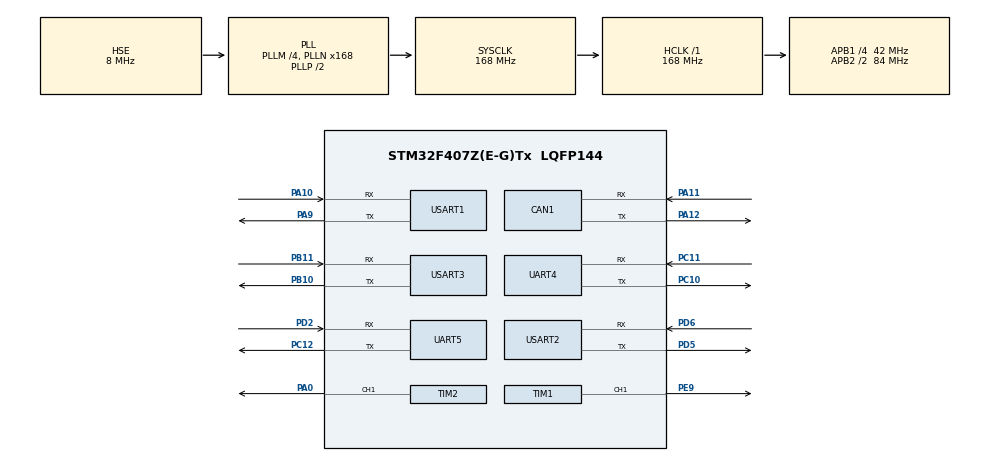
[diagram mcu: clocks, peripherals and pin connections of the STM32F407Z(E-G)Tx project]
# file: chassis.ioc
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CAN1.CalculateTimeBit=1142
CAN1.CalculateTimeQuantum=380.95238095238096
Mcu.Family=STM32F4
Mcu.Name=STM32F407Z(E-G)Tx
Mcu.Package=LQFP144
NVIC.CAN1_RX0_IRQn=true\:0\:0\:false\:false\:true\:true
NVIC.PriorityGroup=NVIC_PRIORITYGROUP_4
NVIC.UART5_IRQn=true\:0\:0\:false\:false\:true\:true
PA0-WKUP.Signal=S_TIM2_CH1_ETR
PA10.Mode=Asynchronous
PA10.Signal=USART1_RX
PA11.Mode=Master
PA11.Signal=CAN1_RX
PA12.Mode=Master
PA12.Signal=CAN1_TX
PA13.Mode=Serial_Wire
PA13.Signal=SYS_JTMS-SWDIO
PA14.Mode=Serial_Wire
PA14.Signal=SYS_JTCK-SWCLK
PA9.Mode=Asynchronous
PA9.Signal=USART1_TX
PB10.Mode=Asynchronous
PB10.Signal=USART3_TX
PB11.Mode=Asynchronous
PB11.Signal=USART3_RX
PC10.Mode=Asynchronous
PC10.Signal=UART4_TX
PC11.Mode=Asynchronous
PC11.Signal=UART4_RX
PC12.Mode=Asynchronous
PC12.Signal=UART5_TX
PD2.Mode=Asynchronous
PD2.Signal=UART5_RX
PD5.Mode=Asynchronous
PD5.Signal=USART2_TX
PD6.Mode=Asynchronous
PD6.Signal=USART2_RX
PE9.Signal=S_TIM1_CH1
PH0-OSC_IN.Mode=HSE-External-Oscillator
PH0-OSC_IN.Signal=RCC_OSC_IN
PH1-OSC_OUT.Mode=HSE-External-Oscillator
PH1-OSC_OUT.Signal=RCC_OSC_OUT
ProjectManager.HeapSize=0x800
ProjectManager.StackSize=0x400
ProjectManager.TargetToolchain=EWARM
RCC.48MHZClocksFreq_Value=84000000
RCC.AHBFreq_Value=168000000
RCC.APB1CLKDivider=RCC_HCLK_DIV4
RCC.APB1Freq_Value=42000000
RCC.APB1TimFreq_Value=84000000
RCC.APB2CLKDivider=RCC_HCLK_DIV2
RCC.APB2Freq_Value=84000000
RCC.APB2TimFreq_Value=168000000
RCC.CortexFreq_Value=168000000
RCC.HCLKFreq_Value=168000000
RCC.HSE_VALUE=8000000
RCC.HSI_VALUE=16000000
RCC.LSE_VALUE=32768
RCC.PLLM=4
RCC.PLLN=168
RCC.PLLSourceVirtual=RCC_PLLSOURCE_HSE
RCC.SYSCLKFreq_VALUE=168000000
RCC.SYSCLKSource=RCC_SYSCLKSOURCE_PLLCLK
RCC.VCOOutputFreq_Value=336000000
SH.S_TIM1_CH1.0=TIM1_CH1,PWM Generation1 CH1
SH.S_TIM2_CH1_ETR.0=TIM2_CH1,PWM Generation1 CH1
TIM1.Channel-PWM\ Generation1\ CH1=TIM_CHANNEL_1
TIM2.Channel-PWM\ Generation1\ CH1=TIM_CHANNEL_1
UART4.VirtualMode=Asynchronous
UART5.VirtualMode=Asynchronous
USART1.VirtualMode=VM_ASYNC
USART2.VirtualMode=VM_ASYNC
USART3.VirtualMode=VM_ASYNC
board=chassis

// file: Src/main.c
/*******************************************************************************
Copyright:      2018/12/18
File name:      main.c
Description:    程序入口，包含系统时钟配置，外设初始化。
Author:         徐铭远，王云轩
Version：       底盘贝塞尔曲线+action全场定位
Data:           2018/12/18 22:36
History:        删去vega.c文件
*******************************************************************************/
#include "main.h"
#include "stm32f4xx_hal.h"
#include "can.h"
#include "tim.h"
#include "usart.h"
#include "gpio.h"
#include "maxon.h"
#include "cmd.h"
#include "cmd_func.h"
#include "chassis.h"
#include "vega.h"
#include "dma.h"

int main_flag = 0;
int chassis_flag = 0;

void SystemClock_Config(void);

void main()
{
    HAL_Init();
    SystemClock_Config();

    MX_GPIO_Init();
    MX_DMA_Init();
    MX_CAN1_Init();
    MX_TIM1_Init();
    MX_UART5_Init();
    MX_USART2_UART_Init();
    MX_USART1_UART_Init();
    MX_USART3_UART_Init();
    MX_UART4_Init();
    MX_TIM2_Init();

    cmd_init();
    can_init();
    chassis_init();

    uprintf(CMD_USART,"start...\r\n");
    main_flag = 1;
    usart_init();//在里面开串口接收中断
    while (1)
    {
        //uprintf(CMD_USART,"start...\r\n");
        usart_exc();
        if(chassis_flag == 1)
        {
            chassis_exe();
            chassis_flag = 0;
        }
    }

}

/** System Clock Configuration
*/
void SystemClock_Config(void)
{

    RCC_OscInitTypeDef RCC_OscInitStruct;
    RCC_ClkInitTypeDef RCC_ClkInitStruct;

    /**Configure the main internal regulator output voltage
    */
    __HAL_RCC_PWR_CLK_ENABLE();

    __HAL_PWR_VOLTAGESCALING_CONFIG(PWR_REGULATOR_VOLTAGE_SCALE1);

    /**Initializes the CPU, AHB and APB busses clocks
    */
    RCC_OscInitStruct.OscillatorType = RCC_OSCILLATORTYPE_HSE;
    RCC_OscInitStruct.HSEState = RCC_HSE_ON;
    RCC_OscInitStruct.PLL.PLLState = RCC_PLL_ON;
    RCC_OscInitStruct.PLL.PLLSource = RCC_PLLSOURCE_HSE;
    RCC_OscInitStruct.PLL.PLLM = 4;
    RCC_OscInitStruct.PLL.PLLN = 168;
    RCC_OscInitStruct.PLL.PLLP = RCC_PLLP_DIV2;
    RCC_OscInitStruct.PLL.PLLQ = 4;
    if (HAL_RCC_OscConfig(&RCC_OscInitStruct) != HAL_OK)
    {
        _Error_Handler(__FILE__, __LINE__);
    }

    /**Initializes the CPU, AHB and APB busses clocks
    */
    RCC_ClkInitStruct.ClockType = RCC_CLOCKTYPE_HCLK|RCC_CLOCKTYPE_SYSCLK
        |RCC_CLOCKTYPE_PCLK1|RCC_CLOCKTYPE_PCLK2;
    RCC_ClkInitStruct.SYSCLKSource = RCC_SYSCLKSOURCE_PLLCLK;
    RCC_ClkInitStruct.AHBCLKDivider = RCC_SYSCLK_DIV1;
    RCC_ClkInitStruct.APB1CLKDivider = RCC_HCLK_DIV4;
    RCC_ClkInitStruct.APB2CLKDivider = RCC_HCLK_DIV2;

    if (HAL_RCC_ClockConfig(&RCC_ClkInitStruct, FLASH_LATENCY_5) != HAL_OK)
    {
        _Error_Handler(__FILE__, __LINE__);
    }

    /**Configure the Systick interrupt time
    */
    HAL_SYSTICK_Config(HAL_RCC_GetHCLKFreq()/1000);

    /**Configure the Systick
    */
    HAL_SYSTICK_CLKSourceConfig(SYSTICK_CLKSOURCE_HCLK);

    /* SysTick_IRQn interrupt configuration */
    HAL_NVIC_SetPriority(SysTick_IRQn, 0, 0);
}

/* USER CODE BEGIN 4 */
void HAL_SYSTICK_Callback(void){
    static int time_1ms_cnt;
    time_1ms_cnt++;
    if( main_flag == 1)
    {
        if(time_1ms_cnt % 10 == 0)
        {
            chassis_flag = 1;
        }
        if(time_1ms_cnt % 50 == 0)
        {

        }
        if(time_1ms_cnt % 500 == 0)
        {

        }
        if(time_1ms_cnt >= 65533)
        {
            time_1ms_cnt = 0;
        }

    }
}

/* USER CODE END 4 */

void _Error_Handler(char * file, int line)
{
    /* USER CODE BEGIN Error_Handler_Debug */
    /* User can add his own implementation to report the HAL error return state */
    while(1)
    {
        uprintf(CMD_USART,"程序废了，老哥，赶紧复位！！！！！！！\r\n");
    }
    /* USER CODE END Error_Handler_Debug */
}

/************************ (C) COPYRIGHT STMicroelectronics *****END OF FILE****/
